VERSION ""

NS_ :

BS_:

BU_: ECU

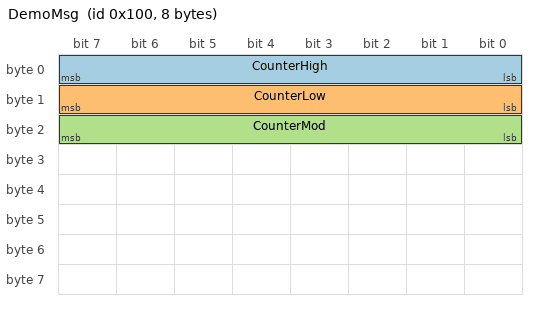
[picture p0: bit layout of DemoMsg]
BO_ 256 DemoMsg: 8 ECU
 SG_ CounterHigh : 0|8@1+ (1,0) [0|255] "" ECU
 SG_ CounterLow : 8|8@1+ (1,0) [0|255] "" ECU
 SG_ CounterMod : 16|8@1+ (1,0) [0|255] "" ECU
